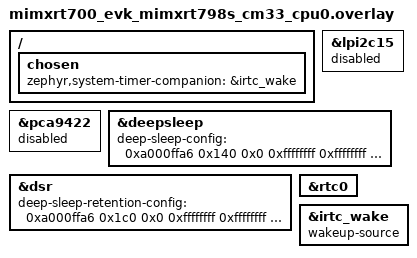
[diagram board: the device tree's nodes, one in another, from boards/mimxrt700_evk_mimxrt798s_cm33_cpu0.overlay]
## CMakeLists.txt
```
# Copyright 2026 NXP
# SPDX-License-Identifier: Apache-2.0

cmake_minimum_required(VERSION 3.20.0)

set(REMOTE_ZEPHYR_DIR ${CMAKE_CURRENT_BINARY_DIR}/../remote/zephyr)

find_package(Zephyr REQUIRED HINTS $ENV{ZEPHYR_BASE})
project(rt700_dual_core_pm)

if(NOT CONFIG_BOARD_MIMXRT700_EVK_MIMXRT798S_CM33_CPU0)
  message(FATAL_ERROR "${BOARD}/${BOARD_QUALIFIERS} is not supported by this sample")
endif()

if(CONFIG_INCLUDE_REMOTE_DIR)
  target_include_directories(zephyr_interface
    INTERFACE ${REMOTE_ZEPHYR_DIR}/include/public)
endif()

target_sources(app PRIVATE src/main.c)
target_include_directories(app PRIVATE
  ${ZEPHYR_BASE}/../modules/hal/nxp/mcux/mcux-sdk-ng/drivers/mu1)
```

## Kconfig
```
# Copyright 2026 NXP
# SPDX-License-Identifier: Apache-2.0

source "Kconfig.zephyr"

config INCLUDE_REMOTE_DIR
	bool "Include remote core header directory"
	help
	  Include remote build header files. The RT700 CPU0 image needs the
	  CPU1 image information header when CONFIG_SECOND_CORE_MCUX is enabled.

config RT700_DUAL_CORE_PM_SLEEP_SECONDS
	int "Power-mode measurement window in seconds"
	default 10
	range 1 3600
	help
	  Number of seconds each active, sleep, or deep-sleep test case runs.
```

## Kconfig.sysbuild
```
# Copyright 2026 NXP
# SPDX-License-Identifier: Apache-2.0

source "share/sysbuild/Kconfig"

config RT700_DUAL_CORE_PM_REMOTE_BOARD
	string "RT700 dual-core PM remote board"
	default "mimxrt700_evk/mimxrt798s/cm33_cpu1" if $(BOARD) = "mimxrt700_evk"
	help
	  Board target used for the CM33 CPU1 remote image.

config RT700_DUAL_CORE_PM_SLEEP_SECONDS
	int "Power-mode measurement window in seconds"
	default 10
	range 1 3600
	help
	  Number of seconds both cores spend in each active, sleep, or
	  deep-sleep measurement window.
```

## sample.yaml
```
sample:
  name: RT700 EVK dual-core power management
common:
  sysbuild: true
  tags:
    - boards
    - nxp
    - pm
  build_only: true
tests:
  sample.boards.nxp.rt700_dual_core_pm:
    platform_allow:
      - mimxrt700_evk/mimxrt798s/cm33_cpu0
    integration_platforms:
      - mimxrt700_evk/mimxrt798s/cm33_cpu0
```

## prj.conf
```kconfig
# Copyright 2026 NXP
# SPDX-License-Identifier: Apache-2.0

CONFIG_PM=y
CONFIG_PRINTK=y

# The deep-sleep-retention (STANDBY) entry/exit path runs on the idle thread
# stack and uses more stack than a plain WFI idle (context save/restore, clock
# reconfiguration). Enlarge the idle stack so it does not overflow.
CONFIG_IDLE_STACK_SIZE=2048

# Interactive menu over the console: read the user's case selection
# character by character.
CONFIG_CONSOLE_SUBSYS=y
CONFIG_CONSOLE_GETCHAR=y
```

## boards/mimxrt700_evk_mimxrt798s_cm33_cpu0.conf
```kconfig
# Copyright 2026 NXP
# SPDX-License-Identifier: Apache-2.0

CONFIG_SECOND_CORE_MCUX=y
CONFIG_INCLUDE_REMOTE_DIR=y
CONFIG_COUNTER=y
CONFIG_MCUX_OS_TIMER_PM_POWERED_OFF=y
```

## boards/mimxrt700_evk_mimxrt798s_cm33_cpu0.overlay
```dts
/*
 * Copyright 2026 NXP
 *
 * SPDX-License-Identifier: Apache-2.0
 */

/*
 * The dual-core PM sample does not use I2C or the on-board PCA9422 PMIC.
 *
 * On CPU0 the LPI2C15 functional clock is sourced from the SENSE domain base
 * clock, which is configured by CPU1 (not CPU0). When the PMIC MFD driver is
 * pulled in it initializes LPI2C15 while its clock rate is still 0, which makes
 * the MCUX LPI2C driver divide by zero during baud-rate setup. Disabling the
 * unused bus (and the PMIC node on it) keeps the sample focused on dual-core
 * power-management coordination over the MU.
 */

&lpi2c15 {
	status = "disabled";
};

&pca9422 {
	status = "disabled";
};

/*
 * In the dual-core PM matrix CPU0 enters deep sleep while CPU1 keeps running
 * (cases 5-7). The default SLEEPCON0 deep-sleep mask gates the SENSE-domain and
 * common main clocks and powers down every oscillator (XTAL, FRO0-2, LPOSC),
 * and the default PDSLEEPCFG2/3 masks power down the SRAM partitions that hold
 * CPU1's code and data (0x5C0000-0x67FFFF). Either one freezes CPU1's core.
 * Override the deep-sleep config so CPU0 deep sleep keeps the clocks and RAM
 * CPU1 depends on alive.
 *
 * deep-sleep-config words map to the SoC power code's excl[] mask (bits to
 * NOT gate / NOT power down):
 *   word0 = SLEEPCON0 SLEEPCFG keep-alive (clocks/oscillators)
 *   word1 = PDSLEEPCFG0 keep-powered      (voltage domains)
 *   word2 = PDSLEEPCFG1 keep-powered
 *   word3 = PDSLEEPCFG2 keep-powered      (SRAM partitions 0-31)
 *   word4 = PDSLEEPCFG3 keep-powered      (SRAM partitions 32-63)
 *   word5 = PDSLEEPCFG4 keep-powered      (caches / OTP / peripherals)
 *   word6 = PDSLEEPCFG5 keep-powered
 *
 * word0 = 0xA000FFA6 keeps: SENSEP/SENSES/COMN main clocks (bits 1,2,5),
 * XTAL/FRO0-2/LPOSC (bits 7-11), all PLLs (bits 12-15) and the FRO0/FRO2
 * output gates (bits 29,31). word1 = 0x140 keeps VDDN_COM fully powered
 * (VNCOM_DSR bit8 + V2NMED_DSR bit6) so CPU0 resumes in place instead of
 * warm-resetting into ROM. word3/word4 = 0xFFFFFFFF keep all SRAM partitions
 * powered so CPU1's image survives CPU0 deep sleep.
 */
&deepsleep {
	deep-sleep-config = <0xa000ffa6 0x140 0x0
			     0xffffffff 0xffffffff 0x400c00 0x0>;
};

/*
 * Deep sleep retention reuses the same dual-core keep-alive mask as deep sleep
 * (case 8: CPU0 DSR while CPU1 is parked in deep sleep). Full deep-sleep
 * retention (FDSR) is a dual-domain mode: it only engages when both the compute
 * and sense domains request deep sleep. Keeping the SENSE / COMN clocks and all
 * SRAM partitions alive lets both cores resume in place afterwards.
 *
 * word1 = 0x1C0 excludes V2COM_DSR (bit7) in addition to VNCOM_DSR (bit8) and
 * V2NMED_DSR (bit6). PCFG0_DSR requests all three, but V2COM_DSR (the shared
 * VDD2 common rail) must only be retained when *every* VDD2/VDDN companion is
 * also retained (PMC rule: "when V2COM_DSR, other VDD2 and VDDN switches should
 * be off"). Since not every VDD2/VDDN companion enters retention here, V2COM_DSR
 * must be excluded - otherwise the PMC enters an inconsistent retention state,
 * the common VDD2/VDDN rail collapses, and CPU0 warm-resets into the boot ROM
 * instead of resuming in place. Excluding it leaves only V2COMP_DSR (CPU0's own
 * compute logic), which together with the FDSR domain bits is exactly what
 * case 8 needs.
 */
&dsr {
	deep-sleep-retention-config = <0xa000ffa6 0x1c0 0x0
				       0xffffffff 0xffffffff 0x400c00 0x0>;
};

/*
 * In DSR (case 8) the OS Timer that drives the system tick loses power because
 * it sits in the VDD2_COMP rail that DSR collapses. Enable the always-on IRTC
 * wake timer as the companion counter so the OS Timer can program a wakeup and
 * resume in place. rtc0 must be okay for its wake-timer child to be usable.
 */
/ {
	chosen {
		zephyr,system-timer-companion = &irtc_wake;
	};
};

&rtc0 {
	status = "okay";
};

&irtc_wake {
	status = "okay";
	wakeup-source;
};
```

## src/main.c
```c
/*
 * Copyright 2026 NXP
 *
 * SPDX-License-Identifier: Apache-2.0
 */

#include <zephyr/kernel.h>
#include <zephyr/console/console.h>
#include <zephyr/pm/pm.h>
#include <zephyr/pm/policy.h>
#include <zephyr/pm/state.h>
#include <zephyr/sys/atomic.h>
#include <zephyr/sys/printk.h>
#include <zephyr/sys/util.h>

#include <fsl_mu.h>

#define RT700_PM_MU_REG kMU_MsgReg0

#define RT700_PM_MSG_CMD_ACTIVE      0x43504d00U
#define RT700_PM_MSG_CMD_SLEEP       0x43504d01U
#define RT700_PM_MSG_CMD_DEEP_SLEEP  0x43504d02U
#define RT700_PM_MSG_CMD_DSR         0x43504d03U
#define RT700_PM_MSG_CMD_GO          0x43504d10U
#define RT700_PM_MSG_ACK_ACTIVE      0x41504d00U
#define RT700_PM_MSG_ACK_SLEEP       0x41504d01U
#define RT700_PM_MSG_ACK_DEEP_SLEEP  0x41504d02U
#define RT700_PM_MSG_ACK_DSR         0x41504d03U
#define RT700_PM_MSG_DONE_ACTIVE     0x44504d00U
#define RT700_PM_MSG_DONE_SLEEP      0x44504d01U
#define RT700_PM_MSG_DONE_DEEP_SLEEP 0x44504d02U
#define RT700_PM_MSG_DONE_DSR        0x44504d03U

enum rt700_pm_mode {
	RT700_PM_MODE_ACTIVE,
	RT700_PM_MODE_SLEEP,
	RT700_PM_MODE_DEEP_SLEEP,
	RT700_PM_MODE_DSR,
};

struct rt700_pm_case {
	const char *name;
	enum rt700_pm_mode cpu0_mode;
	enum rt700_pm_mode cpu1_mode;
};

static const struct rt700_pm_case test_cases[] = {
	{
		.name = "active baseline",
		.cpu0_mode = RT700_PM_MODE_ACTIVE,
		.cpu1_mode = RT700_PM_MODE_ACTIVE,
	},
	{
		.name = "CPU0 sleep, CPU1 active",
		.cpu0_mode = RT700_PM_MODE_SLEEP,
		.cpu1_mode = RT700_PM_MODE_ACTIVE,
	},
	{
		.name = "CPU0 active, CPU1 sleep",
		.cpu0_mode = RT700_PM_MODE_ACTIVE,
		.cpu1_mode = RT700_PM_MODE_SLEEP,
	},
	{
		.name = "CPU0 and CPU1 sleep",
		.cpu0_mode = RT700_PM_MODE_SLEEP,
		.cpu1_mode = RT700_PM_MODE_SLEEP,
	},
	{
		.name = "CPU0 deep sleep, CPU1 active",
		.cpu0_mode = RT700_PM_MODE_DEEP_SLEEP,
		.cpu1_mode = RT700_PM_MODE_ACTIVE,
	},
	{
		.name = "CPU0 active, CPU1 deep sleep",
		.cpu0_mode = RT700_PM_MODE_ACTIVE,
		.cpu1_mode = RT700_PM_MODE_DEEP_SLEEP,
	},
	{
		.name = "CPU0 and CPU1 deep sleep",
		.cpu0_mode = RT700_PM_MODE_DEEP_SLEEP,
		.cpu1_mode = RT700_PM_MODE_DEEP_SLEEP,
	},
	{
		/*
		 * Full deep-sleep retention is a dual-domain (FDSR) mode: it only
		 * engages when both the compute and sense domains request deep
		 * sleep, so CPU1 is parked in deep sleep while CPU0 enters DSR.
		 */
		.name = "CPU0 deep sleep retention, CPU1 deep sleep",
		.cpu0_mode = RT700_PM_MODE_DSR,
		.cpu1_mode = RT700_PM_MODE_DEEP_SLEEP,
	},
};

static atomic_t state_entry_count[PM_STATE_COUNT];
static atomic_t state_exit_count[PM_STATE_COUNT];

static void pm_state_entry(enum pm_state state)
{
	if (state < PM_STATE_COUNT) {
		atomic_inc(&state_entry_count[state]);
	}
}

static void pm_state_exit(enum pm_state state)
{
	if (state < PM_STATE_COUNT) {
		atomic_inc(&state_exit_count[state]);
	}
}

static struct pm_notifier pm_events = {
	.state_entry = pm_state_entry,
	.state_exit = pm_state_exit,
};

static void print_pm_counts(void)
{
	printk("CPU0 PM counts: runtime-idle=%ld/%ld suspend-to-idle=%ld/%ld "
	       "standby=%ld/%ld\n",
	       atomic_get(&state_entry_count[PM_STATE_RUNTIME_IDLE]),
	       atomic_get(&state_exit_count[PM_STATE_RUNTIME_IDLE]),
	       atomic_get(&state_entry_count[PM_STATE_SUSPEND_TO_IDLE]),
	       atomic_get(&state_exit_count[PM_STATE_SUSPEND_TO_IDLE]),
	       atomic_get(&state_entry_count[PM_STATE_STANDBY]),
	       atomic_get(&state_exit_count[PM_STATE_STANDBY]));
}

static uint32_t mode_to_cmd(enum rt700_pm_mode mode)
{
	switch (mode) {
	case RT700_PM_MODE_ACTIVE:
		return RT700_PM_MSG_CMD_ACTIVE;
	case RT700_PM_MODE_SLEEP:
		return RT700_PM_MSG_CMD_SLEEP;
	case RT700_PM_MODE_DEEP_SLEEP:
		return RT700_PM_MSG_CMD_DEEP_SLEEP;
	case RT700_PM_MODE_DSR:
		return RT700_PM_MSG_CMD_DSR;
	default:
		return RT700_PM_MSG_CMD_ACTIVE;
	}
}

static uint32_t mode_to_ack(enum rt700_pm_mode mode)
{
	switch (mode) {
	case RT700_PM_MODE_ACTIVE:
		return RT700_PM_MSG_ACK_ACTIVE;
	case RT700_PM_MODE_SLEEP:
		return RT700_PM_MSG_ACK_SLEEP;
	case RT700_PM_MODE_DEEP_SLEEP:
		return RT700_PM_MSG_ACK_DEEP_SLEEP;
	case RT700_PM_MODE_DSR:
		return RT700_PM_MSG_ACK_DSR;
	default:
		return RT700_PM_MSG_ACK_ACTIVE;
	}
}

static uint32_t mode_to_done(enum rt700_pm_mode mode)
{
	switch (mode) {
	case RT700_PM_MODE_ACTIVE:
		return RT700_PM_MSG_DONE_ACTIVE;
	case RT700_PM_MODE_SLEEP:
		return RT700_PM_MSG_DONE_SLEEP;
	case RT700_PM_MODE_DEEP_SLEEP:
		return RT700_PM_MSG_DONE_DEEP_SLEEP;
	case RT700_PM_MODE_DSR:
		return RT700_PM_MSG_DONE_DSR;
	default:
		return RT700_PM_MSG_DONE_ACTIVE;
	}
}

static const char *mode_to_str(enum rt700_pm_mode mode)
{
	switch (mode) {
	case RT700_PM_MODE_ACTIVE:
		return "active";
	case RT700_PM_MODE_SLEEP:
		return "sleep";
	case RT700_PM_MODE_DEEP_SLEEP:
		return "deep-sleep";
	case RT700_PM_MODE_DSR:
		return "deep-sleep-retention";
	default:
		return "unknown";
	}
}

static uint32_t receive_remote_msg(void)
{
	while ((MU_GetStatusFlags(MU1_MUA) & kMU_Rx0FullFlag) == 0U) {
		k_yield();
	}

	return MU_ReceiveMsgNonBlocking(MU1_MUA, RT700_PM_MU_REG);
}

static void send_remote_msg(uint32_t msg)
{
	(void)MU_SendMsg(MU1_MUA, RT700_PM_MU_REG, msg);
}

static void active_window(void)
{
	for (int i = 0; i < CONFIG_RT700_DUAL_CORE_PM_SLEEP_SECONDS; i++) {
		k_busy_wait(USEC_PER_SEC);
	}
}

static void run_local_window(enum rt700_pm_mode mode)
{
	switch (mode) {
	case RT700_PM_MODE_ACTIVE:
		active_window();
		break;
	case RT700_PM_MODE_SLEEP:
		/*
		 * Suspend-to-idle is locked out at startup, so the idle thread
		 * stays in runtime-idle for the whole window instead of letting
		 * the default policy slide into the deeper state.
		 */
		k_sleep(K_SECONDS(CONFIG_RT700_DUAL_CORE_PM_SLEEP_SECONDS));
		break;
	case RT700_PM_MODE_DEEP_SLEEP:
		/* Temporarily allow suspend-to-idle for this window only. */
		pm_policy_state_lock_put(PM_STATE_SUSPEND_TO_IDLE, PM_ALL_SUBSTATES);
		k_sleep(K_SECONDS(CONFIG_RT700_DUAL_CORE_PM_SLEEP_SECONDS));
		pm_policy_state_lock_get(PM_STATE_SUSPEND_TO_IDLE, PM_ALL_SUBSTATES);
		break;
	case RT700_PM_MODE_DSR:
		/* Temporarily allow standby (deep sleep retention) for this window only. */
		pm_policy_state_lock_put(PM_STATE_STANDBY, PM_ALL_SUBSTATES);
		k_sleep(K_SECONDS(CONFIG_RT700_DUAL_CORE_PM_SLEEP_SECONDS));
		pm_policy_state_lock_get(PM_STATE_STANDBY, PM_ALL_SUBSTATES);
		break;
	default:
		break;
	}
}

static void wait_remote_msg(enum rt700_pm_mode mode, uint32_t expected, const char *phase)
{
	uint32_t msg = receive_remote_msg();

	if (msg != expected) {
		printk("CPU0: unexpected CPU1 %s 0x%08x for %s\n", phase, msg, mode_to_str(mode));
	}
}

static void run_test_case(uint32_t index, const struct rt700_pm_case *test_case)
{
	printk("\nCPU0: case %u: %s\n", index, test_case->name);
	printk("CPU0: local=%s remote=%s window=%d seconds\n", mode_to_str(test_case->cpu0_mode),
	       mode_to_str(test_case->cpu1_mode), CONFIG_RT700_DUAL_CORE_PM_SLEEP_SECONDS);

	send_remote_msg(mode_to_cmd(test_case->cpu1_mode));
	wait_remote_msg(test_case->cpu1_mode, mode_to_ack(test_case->cpu1_mode), "ACK");
	send_remote_msg(RT700_PM_MSG_CMD_GO);

	printk("CPU0: entering %s window\n", mode_to_str(test_case->cpu0_mode));
	run_local_window(test_case->cpu0_mode);
	printk("CPU0: local %s window complete\n", mode_to_str(test_case->cpu0_mode));

	wait_remote_msg(test_case->cpu1_mode, mode_to_done(test_case->cpu1_mode), "DONE");
	print_pm_counts();
}

static void print_menu(void)
{
	printk("\nRT700 dual-core PM menu:\n");
	for (uint32_t i = 0; i < ARRAY_SIZE(test_cases); i++) {
		printk("  %u: %s\n", i + 1U, test_cases[i].name);
	}
	printk("  a: run all cases\n");
	printk("Select a case [1-%u, a]: ", (uint32_t)ARRAY_SIZE(test_cases));
}

/*
 * Block until the user types a valid selection. Returns 1..ARRAY_SIZE for a
 * single case, or 0 to run the whole matrix. Other keys (CR, LF, etc.) are
 * ignored so terminals that send line endings do not pick a case by accident.
 */
static uint32_t read_menu_choice(void)
{
	while (true) {
		int c = console_getchar();

		if (c < 0) {
			continue;
		}

		if ((c >= '1') && (c < ('1' + (int)ARRAY_SIZE(test_cases)))) {
			printk("%c\n", c);
			return (uint32_t)(c - '0');
		}

		if ((c == 'a') || (c == 'A')) {
			printk("%c\n", c);
			return 0U;
		}
	}
}

int main(void)
{
	printk("RT700 dual-core PM sample: CPU0 started on %s\n", CONFIG_BOARD_TARGET);
	printk("CPU0: coverage is active, per-core sleep, coordinated sleep, "
	       "per-core deep-sleep, coordinated deep-sleep, deep-sleep-retention\n");

	console_init();
	pm_notifier_register(&pm_events);

	/*
	 * Lock the deeper states by default so sleep windows stay in
	 * runtime-idle. Deep-sleep and DSR windows unlock them explicitly.
	 */
	pm_policy_state_lock_get(PM_STATE_SUSPEND_TO_IDLE, PM_ALL_SUBSTATES);
	pm_policy_state_lock_get(PM_STATE_STANDBY, PM_ALL_SUBSTATES);

	while (true) {
		print_menu();

		uint32_t choice = read_menu_choice();

		if (choice == 0U) {
			for (uint32_t i = 0; i < ARRAY_SIZE(test_cases); i++) {
				run_test_case(i + 1U, &test_cases[i]);
			}
		} else {
			run_test_case(choice, &test_cases[choice - 1U]);
		}
	}
}
```
